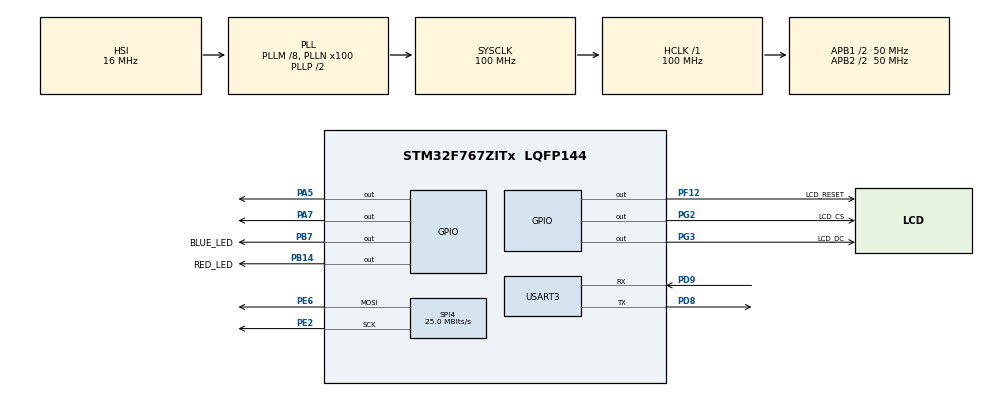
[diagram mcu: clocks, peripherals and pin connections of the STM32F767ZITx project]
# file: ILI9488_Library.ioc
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Mcu.Family=STM32F7
Mcu.Name=STM32F767ZITx
Mcu.Package=LQFP144
NVIC.PriorityGroup=NVIC_PRIORITYGROUP_4
PA5.GPIO_Speed=GPIO_SPEED_FREQ_VERY_HIGH
PA5.Signal=GPIO_Output
PA7.GPIO_Speed=GPIO_SPEED_FREQ_VERY_HIGH
PA7.Signal=GPIO_Output
PB14.GPIO_Label=RED_LED
PB14.Signal=GPIO_Output
PB7.GPIO_Label=BLUE_LED
PB7.Signal=GPIO_Output
PD8.Mode=Multiprocessor_communication
PD8.Signal=USART3_TX
PD9.Mode=Multiprocessor_communication
PD9.Signal=USART3_RX
PE2.Mode=TX_Only_Simplex_Unidirect_Master
PE2.Signal=SPI4_SCK
PE6.Mode=TX_Only_Simplex_Unidirect_Master
PE6.Signal=SPI4_MOSI
PF12.GPIO_Label=LCD_RESET
PF12.GPIO_Speed=GPIO_SPEED_FREQ_VERY_HIGH
PF12.PinState=GPIO_PIN_RESET
PF12.Signal=GPIO_Output
PG2.GPIO_Label=LCD_CS
PG2.GPIO_Speed=GPIO_SPEED_FREQ_VERY_HIGH
PG2.PinState=GPIO_PIN_SET
PG2.Signal=GPIO_Output
PG3.GPIO_Label=LCD_DC
PG3.GPIO_Speed=GPIO_SPEED_FREQ_VERY_HIGH
PG3.Signal=GPIO_Output
ProjectManager.HeapSize=0x200
ProjectManager.StackSize=0x400
ProjectManager.TargetToolchain=STM32CubeIDE
RCC.AHBFreq_Value=100000000
RCC.APB1CLKDivider=RCC_HCLK_DIV2
RCC.APB1Freq_Value=50000000
RCC.APB1TimFreq_Value=100000000
RCC.APB2CLKDivider=RCC_HCLK_DIV2
RCC.APB2Freq_Value=50000000
RCC.APB2TimFreq_Value=100000000
RCC.CortexFreq_Value=100000000
RCC.HCLKFreq_Value=100000000
RCC.HSE_VALUE=25000000
RCC.HSI_VALUE=16000000
RCC.LSE_VALUE=32768
RCC.PLLM=8
RCC.PLLN=100
RCC.SYSCLKFreq_VALUE=100000000
RCC.SYSCLKSource=RCC_SYSCLKSOURCE_PLLCLK
RCC.USBFreq_Value=100000000
RCC.VCOOutputFreq_Value=200000000
SPI4.CalculateBaudRate=25.0 MBits/s
SPI4.Direction=SPI_DIRECTION_2LINES
SPI4.Mode=SPI_MODE_MASTER
SPI4.VirtualType=VM_MASTER
USART3.VirtualMode-Multiprocessor_communication=VM_ASYNC
board=custom

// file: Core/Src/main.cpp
/* USER CODE BEGIN Header */
/**
  ******************************************************************************
  * @file           : main.c
  * @brief          : Main program body
  ******************************************************************************
  * @attention
  *
  * <h2><center>&copy; Copyright (c) 2021 STMicroelectronics.
  * All rights reserved.</center></h2>
  *
  * This software component is licensed by ST under BSD 3-Clause license,
  * the "License"; You may not use this file except in compliance with the
  * License. You may obtain a copy of the License at:
  *                        opensource.org/licenses/BSD-3-Clause
  *
  ******************************************************************************
  */
/* USER CODE END Header */
#include "main.h"

/* USER CODE BEGIN Includes */
#include <stdlib.h>
#include "ILI9488.h"
#include "PortmapIO.h"
#include "PortmapSPI.h"
#include "PortmapUART.h"
/* USER CODE END Includes */

SPI_HandleTypeDef hspi4;

UART_HandleTypeDef huart3;

void SystemClock_Config(void);
static void MX_GPIO_Init(void);
static void MX_USART3_UART_Init(void);
static void MX_SPI4_Init(void);

int main(void)
{

  /* MCU Configuration--------------------------------------------------------*/

  /* Reset of all peripherals, Initializes the Flash interface and the Systick. */
  HAL_Init();

  /* Configure the system clock */
  SystemClock_Config();

  /* Initialize all configured peripherals */
  MX_GPIO_Init();
  MX_USART3_UART_Init();
  MX_SPI4_Init();
  /* USER CODE BEGIN 2 */
//  PortmapSPI lcd_spi =PortmapSPI(&hspi1);
PortmapIO lcd_dc = PortmapIO(GPIOG,GPIO_PIN_3);
PortmapIO lcd_cs = PortmapIO(GPIOG,GPIO_PIN_2);
PortmapIO lcd_rst = PortmapIO(GPIOF,GPIO_PIN_12);
PortmapIO lcd_sck = PortmapIO(GPIOA,GPIO_PIN_5);
PortmapIO lcd_mosi = PortmapIO(GPIOA,GPIO_PIN_7);

     //ILI9488 rpi_lcd = ILI9488(&lcd_cs,&lcd_dc, &lcd_rst, &lcd_spi);
	ILI9488 rpi_lcd = ILI9488(&lcd_cs,&lcd_dc, &lcd_rst, &lcd_sck,&lcd_mosi);
     rpi_lcd.begin();

  /* USER CODE END 2 */

  /* Infinite loop */
  /* USER CODE BEGIN WHILE */
     while (1)
     {
   	  rpi_lcd.fillScreen(ILI9488_BLACK);
   	//  rpi_lcd.fillScreen(ILI9488_RED);
   	//   rpi_lcd.fillScreen(ILI9488_GREEN);
   	//   rpi_lcd.fillScreen(ILI9488_BLUE);
   	//   rpi_lcd.fillScreen(ILI9488_BLACK);
   	  HAL_Delay(50);

    /* USER CODE END WHILE */

     }
}

void SystemClock_Config(void)
{
  RCC_OscInitTypeDef RCC_OscInitStruct = {0};
  RCC_ClkInitTypeDef RCC_ClkInitStruct = {0};
  RCC_PeriphCLKInitTypeDef PeriphClkInitStruct = {0};

  /** Configure the main internal regulator output voltage
  */
  __HAL_RCC_PWR_CLK_ENABLE();
  __HAL_PWR_VOLTAGESCALING_CONFIG(PWR_REGULATOR_VOLTAGE_SCALE3);
  /** Initializes the RCC Oscillators according to the specified parameters
  * in the RCC_OscInitTypeDef structure.
  */
  RCC_OscInitStruct.OscillatorType = RCC_OSCILLATORTYPE_HSI;
  RCC_OscInitStruct.HSIState = RCC_HSI_ON;
  RCC_OscInitStruct.HSICalibrationValue = RCC_HSICALIBRATION_DEFAULT;
  RCC_OscInitStruct.PLL.PLLState = RCC_PLL_ON;
  RCC_OscInitStruct.PLL.PLLSource = RCC_PLLSOURCE_HSI;
  RCC_OscInitStruct.PLL.PLLM = 8;
  RCC_OscInitStruct.PLL.PLLN = 100;
  RCC_OscInitStruct.PLL.PLLP = RCC_PLLP_DIV2;
  RCC_OscInitStruct.PLL.PLLQ = 2;
  if (HAL_RCC_OscConfig(&RCC_OscInitStruct) != HAL_OK)
  {
    Error_Handler();
  }
  /** Activate the Over-Drive mode
  */
  if (HAL_PWREx_EnableOverDrive() != HAL_OK)
  {
    Error_Handler();
  }
  /** Initializes the CPU, AHB and APB buses clocks
  */
  RCC_ClkInitStruct.ClockType = RCC_CLOCKTYPE_HCLK|RCC_CLOCKTYPE_SYSCLK
                              |RCC_CLOCKTYPE_PCLK1|RCC_CLOCKTYPE_PCLK2;
  RCC_ClkInitStruct.SYSCLKSource = RCC_SYSCLKSOURCE_PLLCLK;
  RCC_ClkInitStruct.AHBCLKDivider = RCC_SYSCLK_DIV1;
  RCC_ClkInitStruct.APB1CLKDivider = RCC_HCLK_DIV2;
  RCC_ClkInitStruct.APB2CLKDivider = RCC_HCLK_DIV2;

  if (HAL_RCC_ClockConfig(&RCC_ClkInitStruct, FLASH_LATENCY_3) != HAL_OK)
  {
    Error_Handler();
  }
  PeriphClkInitStruct.PeriphClockSelection = RCC_PERIPHCLK_USART3;
  PeriphClkInitStruct.Usart3ClockSelection = RCC_USART3CLKSOURCE_PCLK1;
  if (HAL_RCCEx_PeriphCLKConfig(&PeriphClkInitStruct) != HAL_OK)
  {
    Error_Handler();
  }
}

static void MX_SPI4_Init(void)
{

  /* SPI4 parameter configuration*/
  hspi4.Instance = SPI4;
  hspi4.Init.Mode = SPI_MODE_MASTER;
  hspi4.Init.Direction = SPI_DIRECTION_2LINES;
  hspi4.Init.DataSize = SPI_DATASIZE_4BIT;
  hspi4.Init.CLKPolarity = SPI_POLARITY_LOW;
  hspi4.Init.CLKPhase = SPI_PHASE_1EDGE;
  hspi4.Init.NSS = SPI_NSS_SOFT;
  hspi4.Init.BaudRatePrescaler = SPI_BAUDRATEPRESCALER_2;
  hspi4.Init.FirstBit = SPI_FIRSTBIT_MSB;
  hspi4.Init.TIMode = SPI_TIMODE_DISABLE;
  hspi4.Init.CRCCalculation = SPI_CRCCALCULATION_DISABLE;
  hspi4.Init.CRCPolynomial = 7;
  hspi4.Init.CRCLength = SPI_CRC_LENGTH_DATASIZE;
  hspi4.Init.NSSPMode = SPI_NSS_PULSE_ENABLE;
  if (HAL_SPI_Init(&hspi4) != HAL_OK)
  {
    Error_Handler();
  }

}

static void MX_USART3_UART_Init(void)
{

  huart3.Instance = USART3;
  huart3.Init.BaudRate = 115200;
  huart3.Init.WordLength = UART_WORDLENGTH_8B;
  huart3.Init.StopBits = UART_STOPBITS_1;
  huart3.Init.Parity = UART_PARITY_NONE;
  huart3.Init.Mode = UART_MODE_TX_RX;
  huart3.Init.HwFlowCtl = UART_HWCONTROL_NONE;
  huart3.Init.OverSampling = UART_OVERSAMPLING_16;
  huart3.Init.OneBitSampling = UART_ONE_BIT_SAMPLE_DISABLE;
  huart3.AdvancedInit.AdvFeatureInit = UART_ADVFEATURE_NO_INIT;
  if (HAL_MultiProcessor_Init(&huart3, 0, UART_WAKEUPMETHOD_IDLELINE) != HAL_OK)
  {
    Error_Handler();
  }

}

static void MX_GPIO_Init(void)
{
  GPIO_InitTypeDef GPIO_InitStruct = {0};

  /* GPIO Ports Clock Enable */
  __HAL_RCC_GPIOE_CLK_ENABLE();
  __HAL_RCC_GPIOA_CLK_ENABLE();
  __HAL_RCC_GPIOF_CLK_ENABLE();
  __HAL_RCC_GPIOB_CLK_ENABLE();
  __HAL_RCC_GPIOD_CLK_ENABLE();
  __HAL_RCC_GPIOG_CLK_ENABLE();

  /*Configure GPIO pin Output Level */
  HAL_GPIO_WritePin(GPIOA, GPIO_PIN_5|GPIO_PIN_7, GPIO_PIN_RESET);

  /*Configure GPIO pin Output Level */
  HAL_GPIO_WritePin(LCD_RESET_GPIO_Port, LCD_RESET_Pin, GPIO_PIN_RESET);

  /*Configure GPIO pin Output Level */
  HAL_GPIO_WritePin(GPIOB, RED_LED_Pin|BLUE_LED_Pin, GPIO_PIN_RESET);

  /*Configure GPIO pin Output Level */
  HAL_GPIO_WritePin(LCD_CS_GPIO_Port, LCD_CS_Pin, GPIO_PIN_SET);

  /*Configure GPIO pin Output Level */
  HAL_GPIO_WritePin(LCD_DC_GPIO_Port, LCD_DC_Pin, GPIO_PIN_RESET);

  /*Configure GPIO pins : PA5 PA7 */
  GPIO_InitStruct.Pin = GPIO_PIN_5|GPIO_PIN_7;
  GPIO_InitStruct.Mode = GPIO_MODE_OUTPUT_PP;
  GPIO_InitStruct.Pull = GPIO_NOPULL;
  GPIO_InitStruct.Speed = GPIO_SPEED_FREQ_VERY_HIGH;
  HAL_GPIO_Init(GPIOA, &GPIO_InitStruct);

  /*Configure GPIO pin : LCD_RESET_Pin */
  GPIO_InitStruct.Pin = LCD_RESET_Pin;
  GPIO_InitStruct.Mode = GPIO_MODE_OUTPUT_PP;
  GPIO_InitStruct.Pull = GPIO_NOPULL;
  GPIO_InitStruct.Speed = GPIO_SPEED_FREQ_VERY_HIGH;
  HAL_GPIO_Init(LCD_RESET_GPIO_Port, &GPIO_InitStruct);

  /*Configure GPIO pins : RED_LED_Pin BLUE_LED_Pin */
  GPIO_InitStruct.Pin = RED_LED_Pin|BLUE_LED_Pin;
  GPIO_InitStruct.Mode = GPIO_MODE_OUTPUT_PP;
  GPIO_InitStruct.Pull = GPIO_NOPULL;
  GPIO_InitStruct.Speed = GPIO_SPEED_FREQ_LOW;
  HAL_GPIO_Init(GPIOB, &GPIO_InitStruct);

  /*Configure GPIO pins : LCD_CS_Pin LCD_DC_Pin */
  GPIO_InitStruct.Pin = LCD_CS_Pin|LCD_DC_Pin;
  GPIO_InitStruct.Mode = GPIO_MODE_OUTPUT_PP;
  GPIO_InitStruct.Pull = GPIO_NOPULL;
  GPIO_InitStruct.Speed = GPIO_SPEED_FREQ_VERY_HIGH;
  HAL_GPIO_Init(GPIOG, &GPIO_InitStruct);

}

void Error_Handler(void)
{
  __disable_irq();
  while (1)
  {
  }
}

/************************ (C) COPYRIGHT STMicroelectronics *****END OF FILE****/
